# platform_designer_hps_system_hps_0_hps register map
Vendor: default_vendor.com; File version: 0.0
Registers are 32-bit, read-write, reset 0x0 unless marked. A register's access mark holds for its fields unless they carry their own. Offsets are from the block's base; [hi:lo] are bit positions; {n}, {i} and the like mark numbered series.

## uart0 — Registers in the UART module
Base 0xFFC02000
Same registers: uart1 0xFFC03000
0x00 rbr_thr_dll — This is a multi-function register. This register holds receives and transmit data and controls the least-signficant 8 bits of the baud rate divisor.
  [7:0] value — Receive Buffer Register: This register contains the data byte received on the serial input port (uart_rxd). The data in this register is valid only if the Data Ready ( bit [0] in the Line Status Register(LSR)) is set to 1. If FIFOs are disabled(bit[0] of Register FCR is set to 0) the data in the RBR must be read before the next data arrives, otherwise it will be overwritten, resulting in an overrun error. If FIFOs are enabled(bit [0] of Register FCR is set to 1) this register accesses the head of the receive FIFO. If the receive FIFO is full, and this register is not read before the next data character arrives, then the data already in the FIFO will be preserved but any incoming data will be lost. An overrun error will also occur. Transmit Holding Register: This register contains data to be transmitted on the serial output port. Data should only be written to the THR when the THR Empty bit [5] of the LSR Register is set to 1. If FIFOs are disabled (bit [0] of Register FCR) is set to 0 and THRE is set to 1, writing a single character to the THR clears the THRE. Any additional writes to the THR before the THRE is set again causes the THR data to be overwritten. If FIFO's are enabled bit [0] of Register FCR is set to 1 and THRE is set up to 128 characters of data may be written to the THR before the FIFO is full. Any attempt to write data when the FIFO is full results in the write data being lost. Divisor Latch Low: This register makes up the lower 8-bits of a 16-bit, Read/write, Divisor Latch register that contains the baud rate divisor for the UART. This register may only be accessed when the DLAB bit [7] of the LCR Register is set to 1. The output baud rate is equal to the serial clock l4_sp_clk frequency divided by sixteen times the value of the baud rate divisor, as follows: baud rate = (serial clock freq) / (16 * divisor) Note that with the Divisor Latch Registers (DLL and DLH) set to zero, the baud clock is disabled and no serial communications will occur. Also, once the DLL is set, at least 8 l4_sp_clk clock cycles should be allowed to pass before transmitting or receiving data.
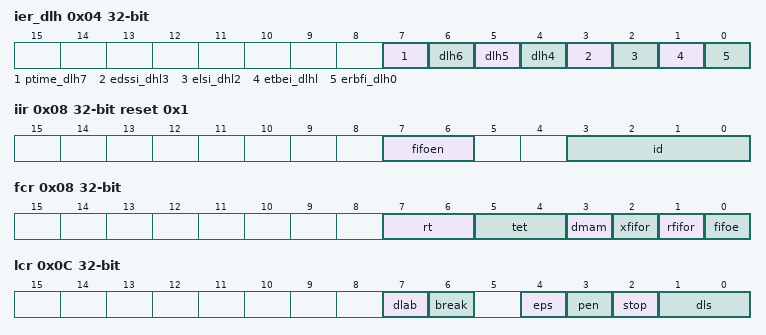
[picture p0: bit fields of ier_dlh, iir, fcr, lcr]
0x04 ier_dlh — This is a multi-function register. This register enables/disables receive and transmit interrupts and also controls the most-significant 8-bits of the baud rate divisor. Divisor Latch High Register: This register is accessed when the DLAB bit [7] of the LCR Register is set to 1.Bits[7:0] contain the high order 8-bits of the baud rate divisor.The output baud rate is equal to the serial clock l4_sp_clk frequency divided by sixteen times the value of the baud rate divisor, as follows: baud rate = (serial clock freq) / (16 * divisor): Note that with the Divisor Latch Registers (DLLand DLH) set to zero, the baud clock is disabled and no serial communications will occur. Also, once the DLL is set, at least 8 l4_sp_clk clock cycles should be allowed to pass before transmitting or receiving data. Interrupt Enable Register: This register may only be accessed when the DLAB bit [7] of the LCR Register is set to 0.Allows control of the Interrupt Enables for transmit and receive functions.
  [7] ptime_dlh7 — Divisor Latch High Register: Bit 7 of DLH value. Interrupt Enable Register: This is used to enable/disable the generation of THRE Interrupt.
    0=disabled; 1=enabled
  [6] dlh6 — Bit 6 of DLH value.
  [5] dlh5 — Bit 5 of DLH value.
  [4] dlh4 — Bit 4 of DLH value.
  [3] edssi_dhl3 — Divisor Latch High Register: Bit 3 of DLH value. Interrupt Enable Register: This is used to enable/disable the generation of Modem Status Interrupts. This is the fourth highest priority interrupt.
    0=disabled; 1=enabled
  [2] elsi_dhl2 — Divisor Latch High Register: Bit 2 of DLH value. Interrupt Enable Register: This is used to enable/disable the generation of Receiver Line Status Interrupt. This is the highest priority interrupt.
    0=disabled; 1=enabled
  [1] etbei_dlhl — Divisor Latch High Register: Bit 1 of DLH value. Interrupt Enable Register: Enable Transmit Holding Register Empty Interrupt. This is used to enable/disable the generation of Transmitter Holding Register Empty Interrupt. This is the third highest priority interrupt.
    0=disabled; 1=enabled
  [0] erbfi_dlh0 — Divisor Latch High Register: Bit 0 of DLH value. Interrupt Enable Register: Used to enable/disable the generation of the Receive Data Available Interrupt and the Character Timeout Interrupt(if FIFO's enabled). These are the second highest priority interrupts.
    0=disabled; 1=enabled
0x08 iir ro reset 0x1 — Returns interrupt identification and FIFO enable/disable when read.
  [7:6] fifoen — This is used to indicate whether the FIFO's are enabled or disabled.
    0=disabled; 3=enabled
  [3:0] id — This indicates the highest priority pending interrupt.
    0=modemstat; 1=nointrpending; 2=thrempty; 4=rxdatavailable; 6=rxlinestat; 12=chartimeout
0x08 fcr wo (reset mask 0xFFFFFF00) — Controls FIFO Operations when written.
  [7:6] rt — This register is configured to implement FIFOs. Bits[7:6], Rx Trigger (or RT): This is used to select the trigger level in the receiver FIFO at which the Received Data Available Interrupt will be generated. In auto flow control mode it is used to determine when the uart_rts_n signal will be de-asserted. It also determines when the uart_dma_rx_req_n signal will be asserted when in certain modes of operation.
    0=onechar; 1=quarterfull; 2=halffull; 3=fullless2
  [5:4] tet — This is used to select the empty threshold level at which the THRE Interrupts will be generated when the mode is active. It also determines when the uart DMA transmit request signal uart_dma_tx_req_n will be asserted when in certain modes of operation.
    0=fifoempty; 1=twochars; 2=quarterfull; 3=halffull
  [3] dmam — This determines the DMA signalling mode used for the uart_dma_tx_req_n and uart_dma_rx_req_n output signals when additional DMA handshaking signals are not selected. DMA mode 0 supports single DMA data transfers at a time. In mode 0, the uart_dma_tx_req_n signal goes active low under the following conditions: -When the Transmitter Holding Register is empty in non-FIFO mode. -When the transmitter FIFO is empty in FIFO mode with Programmable THRE interrupt mode disabled. -When the transmitter FIFO is at or below the programmed threshold with Programmable THRE interrupt mode enabled. It goes inactive under the following conditions -When a single character has been written into the Transmitter Holding Register or transmitter FIFO with Programmable THRE interrupt mode disabled. -When the transmitter FIFO is above the threshold with Programmable THRE interrupt mode enabled. DMA mode 1 supports multi-DMA data transfers, where multiple transfers are made continuously until the receiver FIFO has been emptied or the transmit FIFO has been filled. In mode 1 the uart_dma_tx_req_n signal is asserted under the following conditions: -When the transmitter FIFO is empty with Programmable THRE interrupt mode disabled. -When the transmitter FIFO is at or below the programmed threshold with Programmable THRE interrupt mode enabled.
    0=single; 1=multiple
  [2] xfifor — Resets the control portion of the transmit FIFO and treats the FIFO as empty. This will also de-assert the DMA Tx request and single signals when additional DMA handshaking is used. Note that this bit is 'self-clearing' and it is not necessary to clear this bit.
    0=noreset; 1=reset
  [1] rfifor — Resets the control portion of the receive FIFO and treats the FIFO as empty. This will also de-assert the DMA Rxrequest and single signals. Note that this bit is self-clearing' and it is not necessary to clear this bit.
    0=noreset; 1=reset
  [0] fifoe — Enables/disables the transmit (Tx) and receive (Rx ) FIFO's. Whenever the value of this bit is changed both the Tx and Rx controller portion of FIFO's will be reset.
    0=disabled; 1=enabled
0x0C lcr — Formats serial data.
  [7] dlab — Used to enable reading and writing of the Divisor Latch register (DLL and DLH) to set the baud rate of the UART. This bit must be cleared after initial baud rate setup in order to access other registers.
  [6] break — This is used to cause a break condition to be transmitted to the receiving device. If set to one the serial output is forced to the spacing (logic 0) state. When not in Loopback Mode, as determined by MCR[4], the sout line is forced low until the Break bit is cleared. When in Loopback Mode, the break condition is internally looped back to the receiver and the sir_out_n line is forced low.
  [4] eps — This is used to select between even and odd parity, when parity is enabled (PEN set to one). If set to one, an even number of logic '1's is transmitted or checked. If set to zero, an odd number of logic '1's is transmitted or checked.
    0=oddpar; 1=evenpar
  [3] pen — This bit is used to enable and disable parity generation and detection in a transmitted and received data character.
    0=disabled; 1=enabled
  [2] stop — Number of stop bits. Used to select the number of stop bits per character that the peripheral will transmit and receive.Note that regardless of the number of stop bits selected the receiver will only check the first stop bit.
    0=onestop; 1=onepoint5stop
  [1:0] dls — Data Length Select.Selects the number of data bits per character that the peripheral will transmit and receive.
    {v}=length{v+5} (v=0..3)
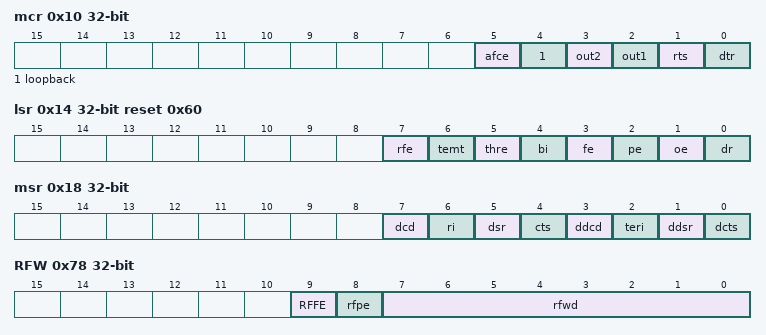
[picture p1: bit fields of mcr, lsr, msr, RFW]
0x10 mcr — Reports various operations of the modem signals
  [5] afce — When FIFOs are enabled, the Auto Flow Control enable bits are active.
    0=disabled; 1=enabled
  [4] loopback — This is used to put the UART into a diagnostic mode for test purposes. If UART mode is NOT active, bit [6] of the modem control register MCR is set to zero, data on the sout line is held high, while serial data output is looped back to the sin line, internally. In this mode all the interrupts are fully functional. Also, in loopback mode, the modem control inputs (uart_dsr_n, uart_cts_n, uart_ri_n, uart_dcd_n) are disconnected and the modem control outputs (uart_dtr_n, uart_rts_n, uart_out1_n, uart_out2_n) are loopedback to the inputs, internally.
  [3] out2 — This is used to directly control the user-designated uart_out2_n output. The value written to this location is inverted and driven out on uart_out2_n Note: In Loopback mode bit 4 of the modem control register (MCR) is set to one, the uart_out2_n output is held inactive high while the value of this location is internally looped back to an input.
    0=logic1; 1=logic0
  [2] out1 — The value written to this location is inverted and driven out on uart_out1_n pin. Note that in Loopback mode (MCR[4] set to one), the uart_out1_n output is held inactive high while the value of this location is internally looped back to an input.
    0=logic1; 1=logic0
  [1] rts — This is used to directly control the Request to Send (uart_rts_n) output. The Request to Send (uart_rts_n) output is used to inform the modem or data set that the UART is ready to exchange data. When Auto RTS Flow Control is not enabled (MCR[5] set to zero), the uart_rts_n signal is set low by programming MCR[1] (RTS) to a high. If Auto Flow Control is active (MCR[5] set to one) and FIFO's enable (FCR[0] set to one), the uart_rts_n output is controlled in the same way, but is also gated with the receiver FIFO threshold trigger (uart_rts_n is inactive high when above the threshold). The uart_rts_n signal will be de-asserted when MCR[1] is set low. Note that in Loopback mode (MCR[4] set to one), the uart_rts_n output is held inactive high while the value of this location is internally looped back to an input.
    0=logic1; 1=logic0
  [0] dtr — This is used to directly control the Data Terminal Ready output. The value written to this location is inverted and driven out on uart_dtr_n, that is: The Data Terminal Ready output is used to inform the modem or data set that the UART is ready to establish communications. Note that Loopback mode bit [4] of MCR is set to one, the uart_dtr_n output is held inactive high while the value of this location is internally looped back to an input.
    0=logic1; 1=logic0
0x14 lsr ro reset 0x60 — Reports status of transmit and receive.
  [7] rfe — This bit is only relevant when FIFO's are enabled (FCR[0] set to one). This is used to indicate if there is at least one parity error, framing error, or break indication in the FIFO. This bit is cleared when the LSR is read and the character with the error is at the top of the receiver FIFO and there are no subsequent errors in the FIFO.
    0=noerr; 1=err
  [6] temt — If in FIFO mode and FIFO's enabled (FCR[0] set to one), this bit is set whenever the Transmitter Shift Register and the FIFO are both empty. If FIFO's are disabled, this bit is set whenever the Transmitter Holding Register and the Transmitter Shift Register are both empty.
    0=notempty; 1=empty
  [5] thre — If THRE mode is disabled (IER[7] set to zero) this bit indicates that the THR or Tx FIFO is empty. This bit is set whenever data is transferred from the THR or Tx FIFO to the transmitter shift register and no new data has been written to the THR or Tx FIFO. This also causes a THRE Interrupt to occur, if the THRE Interrupt is enabled. If both THRE and FIFOs are enabled, both (IER[7] set to one and FCR[0] set to one respectively), the functionality will indicate the transmitter FIFO is full, and no longer controls THRE interrupts, which are then controlled by the FCR[5:4] thresholdsetting.
  [4] bi — This is used to indicate the detection of a break sequence on the serial input data. Set whenever the serial input, sin, is held in a logic 0 state for longer than the sum of start time + data bits + parity + stop bits. A break condition on serial input causes one and only one character, consisting of all zeros, to be received by the UART. The character associated with the break condition is carried through the FIFO and is revealed when the character is at the top of the FIFO. Reading the LSR clears the BI bit.
  [3] fe — This is used to indicate the occurrence of a framing error in the receiver. A framing error occurs when the receiver does not detect a valid STOP bit in the received data. In the FIFO mode, since the framing error is associated with a character received, it is revealed when the character with the framing error is at the top of the FIFO. When a framing error occurs the UART will try to resynchronize. It does this by assuming that the error was due to the start bit of the next character and then continues receiving the other bit i.e. data, and/or parity and stop. It should be noted that the Framing Error (FE) bit(LSR[3]) will be set if a break interrupt has occurred, as indicated by a Break Interrupt BIT bit (LSR[4]). Reading the LSR clears the FE bit.
    0=noframeerr; 1=frameerr
  [2] pe — This is used to indicate the occurrence of a parity error in the receiver if the Parity Enable (PEN) bit (LCR[3]) is set. Since the parity error is associated with a character received, it is revealed when the character with the parity error arrives at the top of the FIFO. It should be noted that the Parity Error (PE) bit (LSR[2]) will be set if a break interrupt has occurred, as indicated by Break Interrupt (BI) bit (LSR[4]). Reading the LSR clears the PE bit.
    0=noparityerr; 1=parityerr
  [1] oe — This is used to indicate the occurrence of an overrun error. This occurs if a new data character was received before the previous data was read. In the non-FIFO mode, the OE bit is set when a new character arrives in the receiver before the previous character was read from the RBR. When this happens, the data in the RBR is overwritten. In the FIFO mode, an overrun error occurs when the FIFO is full and new character arrives at the receiver. The data in the FIFO is retained and the data in the receive shift register is lost.Reading the LSR clears the OE bit.
    0=nooverrun; 1=overrun
  [0] dr — This is used to indicate that the receiver contains at least one character in the RBR or the receiver FIFO. This bit is cleared when the RBR is read in the non-FIFO mode, or when the receiver FIFO is empty, in the FIFO mode.
    0=nodatardy; 1=datardy
0x18 msr ro — It should be noted that whenever bits 0, 1, 2 or 3 are set to logic one, to indicate a change on the modem control inputs, a modem status interrupt will be generated if enabled via the IER regardless of when the change occurred. Since the delta bits (bits 0, 1, 3) can get set after a reset if their respective modem signals are active (see individual bits for details), a read of the MSR after reset can be performed to prevent unwanted interrupts.
  [7] dcd — This is used to indicate the current state of the modem control line uart_dcd_n. That is this bit is the complement uart_dcd_n. When the Data Carrier Detect input (uart_dcd_n) is asserted it is an indication that the carrier has been detected by the modem or data set. In Loopback Mode (MCR[4] set to one), DCD is the same as MCR[3] (uart_out2).
    0=logic1; 1=logic0
  [6] ri — This bit is used to indicate the current state of the modem control line uart_ri_n. That is this bit is the complement uart_ri_n. When the Ring Indicator input (uart_ri_n) is asserted it is an indication that a telephone ringing signal has been received by the modem or data set. In Loopback Mode bit [4] of register MCR set to one, RI is the same as bit [2] uart_out1_n of register MCR.
    0=logic1; 1=logic0
  [5] dsr — This is used to indicate the current state of the modem control line uart_dsr_n. That is this bit is the complement f uart_dsr_n. When the Data Set Ready input (uart_dsr_n) is asserted it is an indication that the modem or data set is ready to establish communications with the uart. In Loopback Mode bit [4] of register MCR is set to one, DSR is the same as bit [0] (DTR) of register MCR.
    0=logic1; 1=logic0
  [4] cts — This is used to indicate the current state of the modem control line uart_cts_n. That is, this bit is the complement uart_cts_n. When the Clear to Send input (uart_cts_n) is asserted it is an indication that the modem or data set is ready to exchange data with the uart. In Loopback Mode bit [4] of register MCR is set to one, CTS is the same as bit [1] RTS of register MCR.
    0=logic1; 1=logic0
  [3] ddcd — This is used to indicate that the modem control line dcd_n has changed since the last time the MSR was read. Reading the MSR clears the DDCD bit. In Loopback Mode bit [4] of register MCR is set to one, DDCD reflects changes bit [3] uart_out2 of register MCR. Note: If the DDCD bit is not set and the uart_dcd_n signal is asserted (low) and a reset occurs (software or otherwise), then the DDCD bit will get set when the reset is removed if the uart_dcd_n signal remains asserted.
    0=nochg; 1=chg
  [2] teri — This is used to indicate that a change on the input uart_ri_n (from an active low, to an inactive high state) has occurred since the last time the MSR was read. Reading the MSR clears the TERI bit. In Loopback Mode bit [4] of register MCR is set to one, TERI reflects when bit [2] of register MCR has changed state from a high to a low.
    0=nochg; 1=chg
  [1] ddsr — This is used to indicate that the modem control line uart_dsr_n has changed since the last time the MSR was read. Reading the MSR clears the DDSR bit.In Loopback Mode (MCR[4] set to one), DDSR reflects changes on bit [0] DTR of register MCR . Note, if the DDSR bit is not set and the uart_dsr_n signal is asserted (low) and a reset occurs (software or otherwise), then the DDSR bit will get set when the reset is removed if the uart_dsr_n signal remains asserted.
    0=nochg; 1=chg
  [0] dcts — This is used to indicate that the modem control line uart_cts_n has changed since the last time the MSR was read. That is: Reading the MSR clears the DCTS bit. In Loopback Mode bit [4] of MCR set to one, DCTS reflects changes on bit [1] RTS of register MCR. Note: If the DCTS bit is not set and the uart_cts_n signal is asserted (low) and a reset occurs (software or otherwise), then the DCTS bit will get set when the reset is removed if the uart_cts_n signal remains asserted.
    0=nochg; 1=chg
0x1C scr — Scratchpad Register
  [7:0] scr — This register is for programmers to use as a temporary storage space.
0x30 srbr — Used to accomadate burst accesses from the master.
  [7:0] srbr — This is a shadow register for the RBR and has been allocated one 32-bit location so as to accommodate burst accesses from the master.This register contains the data byte received on the serial input port (sin). The data in this register is valid only if the Data Ready (DR) bit in the Line status Register (LSR) is set. If FIFOs are disabled, bit [0] of register FCR set to zero, the data in the RBR must be read before the next data arrives, otherwise it will be overwritten, resulting in an overrun error. If FIFOs are enabled (FCR[0] set to one), this register accesses the head of the receive FIFO. If the receive FIFO is full and this register is not read before the next data character arrives, then the data already in the FIFO will be preserved but any incoming data will be lost. An overrun error will also occur.
0x34 sthr — Used to accomadate burst accesses from the master.
  [7:0] sthr — This is a shadow register for the THR and has been allocated sixteen 32-bit locations so as to accommodate burst accesses from the master. This register contains data to be transmitted on the serial output port (sout). Data should only be written to the THR when the THR Empty (THRE) bit (LSR[5]) is set. If FIFO's are disabled bit [0] of register FCR set to zero and THRE is set, writing a single character to the THR clears the THRE. Any additional writes to the THR before the THRE is set again causes the THR data to be overwritten. If FIFO's are enabled bit [0] of register FCR set to one and THRE is set, 128 characters of data may be written to the THR before the FIFO is full. The UART FIFO depth is configured for 128 characters. Any attempt to write data when the FIFO is full results in the write data being lost.
0x70 far — This register is used in FIFO access testing.
  [0] srbr_sthr — This register is used to enable a FIFO access mode for testing, so that the receive FIFO can be written by the master and the transmit FIFO can be read by the master when FIFO's are enabled. When FIFO's are not enabled it allows the RBR to be written by the master and the THR to be read by the master Note: That when the FIFO access mode is enabled/disabled, the control portion of the receive FIFO and transmit FIFO is reset and the FIFO's are treated as empty.
    0=disabled; 1=enabled
0x74 tfr ro — Used in FIFO Access test mode.
  [7:0] tfr — These bits are only valid when FIFO access mode is enabled (FAR[0] is set to one). When FIFO's are enabled, reading this register gives the data at the top of the transmit FIFO. Each consecutive read pops the transmit FIFO and gives the next data value that is currently at the top of the FIFO. When FIFO's are not enabled, reading this register gives the data in the THR.
0x78 RFW wo — Used only with FIFO access test mode.
  [9] RFFE — These bits are only valid when FIFO access mode is enabled (FAR[0] is set to one). When FIFO's are enabled, this bit is used to write framing error detection information to the receive FIFO. When FIFO's are not enabled, this bit is used to write framing error detection information to the RBR.
  [8] rfpe — These bits are only valid when FIFO access mode is enabled (FAR[0] is set to one). When FIFO's are enabled, this bit is used to write parity error detection information to the receive FIFO. When FIFO's are not enabled, this bit is used to write parity error detection information to the RBR.
  [7:0] rfwd — These bits are only valid when FIFO access mode is enabled (FAR[0] is set to one). When FIFO's are enabled, the data that is written to the RFWD is pushed into the receive FIFO. Each consecutive write pushes the new data to the next write location in the receive FIFO. When FIFO's are not enabled, the data that is written to the RFWD is pushed into the RBR.
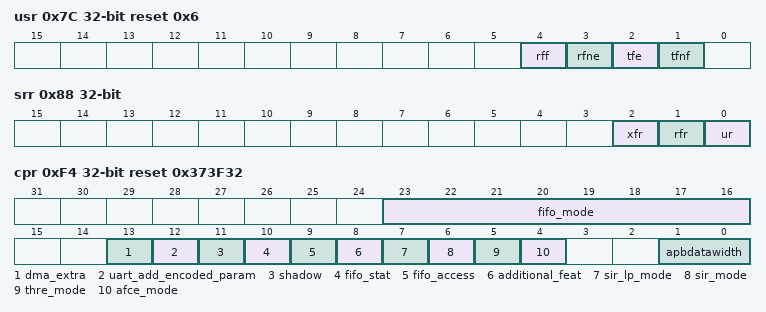
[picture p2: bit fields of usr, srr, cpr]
0x7C usr ro reset 0x6 — Status of FIFO Operations.
  [4] rff — This Bit is used to indicate that the receive FIFO is completely full. This bit is cleared when the Rx FIFO is no longer full.
    0=notfull; 1=full
  [3] rfne — This Bit is used to indicate that the receive FIFO contains one or more entries. This bit is cleared when the Rx FIFO is empty.
    0=empty; 1=notempty
  [2] tfe — This is used to indicate that the transmit FIFO is completely empty. This bit is cleared when the Tx FIFO is no longer empty.
    0=notempty; 1=empty
  [1] tfnf — This Bit is used to indicate that the transmit FIFO in not full. This bit is cleared when the Tx FIFO is full.
    0=full; 1=notfull
0x80 tfl ro — This register is used to specify the number of data entries in the Tx FIFO. Status Bits in USR register monitor the FIFO state.
  [4:0] tfl — This indicates the number of data entries in the transmit FIFO.
0x84 rfl ro — This register is used to specify the number of data entries in the Tx FIFO. Status Bits in USR register monitor the FIFO state.
  [4:0] rfl — This indicates the number of data entries in the receive FIFO.
0x88 srr wo — Provides Software Resets for Tx/Rx FIFO's and the uart.
  [all] fields
    0=noreset; 1=reset
  [2] xfr — This is a shadow register forthe Tx FIFO Reset bit (FCR[2]). This can be used to remove the burden on software having to store previously written FCR values (which are pretty static) just to reset the transmit FIFO.This resets the control portion of the transmit FIFO and treats the FIFO as empty. This will also de-assert the DMA Tx request and single signals.
  [1] rfr — This is a shadow register for the Rx FIFO Reset bit (FCR[1]). This can be used to remove the burden on software having to store previously written FCR values (which are pretty static) just to reset the receive FIFO. This resets the control portion of the receive FIFO and treats the FIFO as empty. This will also de-assert the DMA Rx request and single signals. Note that this bit is 'self-clearing' and it is not necessary to clear this bit.
  [0] ur — This asynchronously resets the UART and synchronously removes the reset assertion.
0x8C srts — This is a shadow register for the RTS status (MCR[1]), this can be used to remove the burden of having to performing a read modify write on the MCR.
  [0] srts — This is used to directly control the Request to Send (uart_rts_n) output. The Request to Send (uart_rts_n) output is used to inform the modem or data set that the UART is read to exchange data. The uart_rts_n signal is set low by programming MCR[1] (RTS) to a high. In Auto Flow Control, (MCR[5] set to one) and FIFO's are enabled (FCR[0] set to one), the uart_rts_n output is controlled in the same way, but is also gated with the receiver FIFO threshold trigger (uart_rts_n is inactive high when above the threshold). Note that in Loopback mode (MCR[4] set to one), the uart_rts_n output is held inactive high while the value of this location is internally looped back to an input.
    1=logic0; 0=logic1
0x90 sbcr — This is a shadow register for the Break bit [6] of the register LCR. This can be used to remove the burden of having to performing a read modify write on the LCR.
  [0] sbcr — This is used to cause a break condition to be transmitted to the receiving device. If set to one the serial output is forced to the spacing (logic 0) state. When not in Loopback Mode, as determined by MCR[4], the uart_txd line is forced low until the Break bit is cleared. When in Loopback Mode, the break condition is internally looped back to the receiver.
    0=disabled; 1=enabled
0x94 sdmam — This is a shadow register for the DMA mode bit (FCR[3]).
  [0] sdmam — This can be used to remove the burden of having to store the previously written value to the FCR in memory and having to mask this value so that only the DMA Mode bit gets updated.
    0=single; 1=multiple
0x98 sfe — This is a shadow register for the FIFO enable bit [0] of register FCR.
  [0] sfe — This can be used to remove the burden of having to store the previously written value to the FCR in memory and having to mask this value so that only the FIFO enable bit gets updated. This enables/disables the transmit (Tx) and receive (Rx ) FIFO's. If this bit is set to zero (disabled) after being enabled then both the Tx and Rx controller portion of FIFO's will be reset.
    0=disabled; 1=enabled
0x9C srt — This is a shadow register for the Rx trigger bits (FCR[7:6]).
  [1:0] srt — This can be used to remove the burden of having to store the previously written value to the FCR in memory and having to mask this value so that only the Rx trigger bit gets updated. This is used to select the trigger level in the receiver FIFO at which the Received Data Available Interrupt will be generated. It also determines when the uart_dma_rx_req_n signal will be asserted when DMA Mode (FCR[3]) is set to one. The enum below shows trigger levels that are supported.
    0=onechar; 1=quarterfull; 2=halffull; 3=fullless2
0xA0 stet — This is a shadow register for the Tx empty trigger bits (FCR[5:4]).
  [1:0] stet — This can be used to remove the burden of having to store the previously written value to the FCR in memory and having to mask this value so that only the Tx empty trigger bit gets updated. This is used to select the empty threshold level at which the THRE Interrupts will be generated when the mode is active. These threshold levels are also described in. The enum trigger levels are supported.
    0=fifoempty; 1=twochars; 2=quarterfull; 3=halffull
0xA4 htx — Used to halt transmission for testing.
  [0] htx — This register is use to halt transmissions for testing, so that the transmit FIFO can be filled by the master when FIFO's are enabled. Note, if FIFO's are not enabled, the setting of the halt Tx register will have no effect on operation.
    0=disabled; 1=enabled
0xA8 dmasa wo — DMA Operation Control
  [0] dmasa — This register is used to perform DMA software acknowledge if a transfer needs to be terminated due to an error condition. For example, if the DMA disables the channel, then the uart should clear its request. This will cause the Tx request, Tx single, Rx request and Rx single signals to de-assert. Note that this bit is 'self-clearing' and it is not necessary to clear this bit.
0xF4 cpr ro reset 0x373F32 — Describes various fixed hardware setups states.
  [23:16] fifo_mode — Receiver and Transmitter FIFO depth in bytes.
    128=fifo128bytes
  [13] dma_extra — Configures the peripheral to have four additional DMA signals on the interface.
    1=enabled
  [12] uart_add_encoded_param — Configures the peripheral to have a configuration identification register.
    1=enabled
  [11] shadow — Configures the peripheral to have seven additional registers that shadow some of the existing register bits that are regularly modified by software. These can be used to reduce the software overhead that is introduced by having to perform read-modify writes.
    1=enabled
  [10] fifo_stat — Configures the peripheral to have three additional FIFO status registers.
    1=enabled
  [9] fifo_access — Configures the peripheral to have a programmable FIFO access mode. This is used for test purposes, to allow the receiver FIFO to be written and the transmit FIFO to be read when FIFOs are implemented and enabled.
    1=enabled
  [8] additional_feat — Configures the uart to include fifo status register, shadow registers and encoded parameter register.
    1=enabled
  [7] sir_lp_mode — LP Sir Mode not used in this application.
    0=disabled
  [6] sir_mode — Sir mode not used in this application.
    0=disabled
  [5] thre_mode — Programmable Transmitter Hold Register Empty interrupt
    1=enabled
  [4] afce_mode — Allows auto flow control.
    1=enabled
  [1:0] apbdatawidth — Fixed to support an ABP data bus width of 32-bits.
    2=width32bits
0xF8 ucv ro reset 0x3331312A — Used only with Additional Features
  [31:0] uart_component_version — ASCII value for each number in the version, followed by *For example 32_30_31_2A represents the version 2.01a
0xFC ctr ro reset 0x44570110 — Describes a hex value associated with the component.
  [31:0] peripheral_id — This register contains the peripherals identification code.
